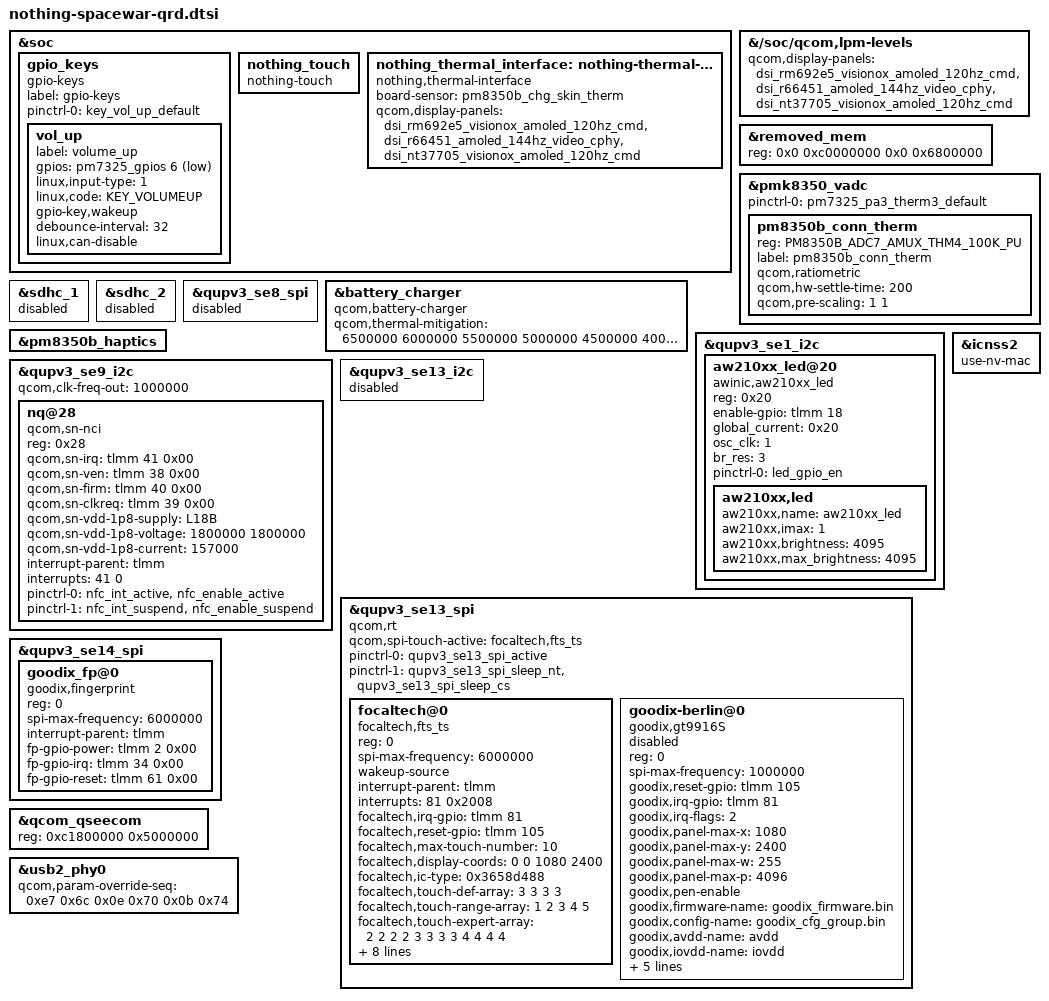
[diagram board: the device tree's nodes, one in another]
// This file is for attribution of nothing spacewar platform only

#include <dt-bindings/gpio/gpio.h>
#include <dt-bindings/input/input.h>
#include "display/nothing-spacewar-sde-display.dtsi"

&soc {
	gpio_keys {
		compatible = "gpio-keys";
		label = "gpio-keys";

		pinctrl-names = "default";
		pinctrl-0 = <&key_vol_up_default>;

		vol_up {
			label = "volume_up";
			gpios = <&pm7325_gpios 6 GPIO_ACTIVE_LOW>;
			linux,input-type = <1>;
			linux,code = <KEY_VOLUMEUP>;
			gpio-key,wakeup;
			debounce-interval = <32>;
			linux,can-disable;
		};
	};

	nothing_touch {
		compatible = "nothing-touch";
		status = "okay";

	};

	nothing_thermal_interface: nothing-thermal-interface {
		compatible = "nothing,thermal-interface";
		board-sensor = "pm8350b_chg_skin_therm";
		qcom,display-panels = <&dsi_rm692e5_visionox_amoled_120hz_cmd
				       &dsi_r66451_amoled_144hz_video_cphy
				       &dsi_nt37705_visionox_amoled_120hz_cmd>;
	};
};

&{/soc/qcom,lpm-levels} {
	qcom,display-panels = <&dsi_rm692e5_visionox_amoled_120hz_cmd
			       &dsi_r66451_amoled_144hz_video_cphy
			       &dsi_nt37705_visionox_amoled_120hz_cmd>;
};

&removed_mem {
	reg = <0x0 0xc0000000 0x0 0x6800000>;
};

/*
 * PMK8350 device specific diff for Nothing Spacewar platform
 */
&pmk8350_vadc {
	pinctrl-names = "default";
	pinctrl-0 = <&pm7325_pa3_therm3_default>;

	pm8350b_conn_therm {
		reg = <PM8350B_ADC7_AMUX_THM4_100K_PU>;
		label = "pm8350b_conn_therm";
		qcom,ratiometric;
		qcom,hw-settle-time = <200>;
		qcom,pre-scaling = <1 1>;
	};
};

&sdhc_1 {
	status = "disabled";
};

&sdhc_2 {
	status = "disabled";
};

&qupv3_se8_spi {
	status = "disabled";
};

&battery_charger {
	compatible = "qcom,battery-charger";
	qcom,thermal-mitigation = <6500000 6000000 5500000 5000000 4500000 4000000
				3500000 3000000 2650000 2200000 1800000 1400000
				1000000 600000 300000 0>;
	#cooling-cells = <2>;
};

&pm8350b_haptics {
	status = "okay";
};

&qupv3_se1_i2c {
	status = "okay";

	aw210xx_led@20 {
		compatible = "awinic,aw210xx_led";
		reg = <0x20>;
		enable-gpio = <&tlmm 18 0x00>;
		global_current = <0x20>;
		osc_clk = <1>;
		br_res = <3>;
		pinctrl-names = "default";
		pinctrl-0 = <&led_gpio_en>;
		status = "okay";
		aw210xx,led {
			aw210xx,name = "aw210xx_led";
			aw210xx,imax = <1>;
			aw210xx,brightness = <4095>;
			aw210xx,max_brightness = <4095>;
		};
	};
};

&qupv3_se9_i2c {
	status = "okay";
	qcom,clk-freq-out = <1000000>;
	#address-cells = <1>;
	#size-cells = <0>;

	nq@28 {
		compatible = "qcom,sn-nci";
		reg = <0x28>;
		qcom,sn-irq = <&tlmm 41 0x00>;
		qcom,sn-ven = <&tlmm 38 0x00>;
		qcom,sn-firm = <&tlmm 40 0x00>;
		qcom,sn-clkreq = <&tlmm 39 0x00>;
		qcom,sn-vdd-1p8-supply = <&L18B>;
		qcom,sn-vdd-1p8-voltage = <1800000 1800000>;
		qcom,sn-vdd-1p8-current = <157000>;
		interrupt-parent = <&tlmm>;
		interrupts = <41 0>;
		interrupt-names = "nfc_irq";
		pinctrl-names = "nfc_active", "nfc_suspend";
		pinctrl-0 = <&nfc_int_active &nfc_enable_active>;
		pinctrl-1 = <&nfc_int_suspend &nfc_enable_suspend>;
		status = "okay";
	};
};

&qupv3_se13_i2c {
	status = "disabled";
};

&qupv3_se13_spi {
	status = "okay";
	qcom,rt;
	qcom,spi-touch-active = "focaltech,fts_ts";
	pinctrl-names = "default", "sleep";
	pinctrl-0 = <&qupv3_se13_spi_active>;
	pinctrl-1 = <&qupv3_se13_spi_sleep_nt &qupv3_se13_spi_sleep_cs>;
	#address-cells = <1>;
	#size-cells = <0>;

	/* FocalTech FT5662 */
	focaltech@0 {
		status = "okay";
		compatible = "focaltech,fts_ts";
		reg = <0>;
		spi-max-frequency = <6000000>;
		wakeup-source;

		interrupt-parent = <&tlmm>;
		interrupts = <81 0x2008>;

		focaltech,irq-gpio = <&tlmm 81 0x2008>;
		focaltech,reset-gpio = <&tlmm 105 0x00>;
		focaltech,max-touch-number = <10>;
		focaltech,display-coords = <0 0 1080 2400>;
		focaltech,ic-type = <0x3658d488>;

		/* Nothing touch-feature tuning */
		focaltech,touch-def-array = <3 3 3 3>;
		focaltech,touch-range-array = <1 2 3 4 5>;
		focaltech,touch-expert-array = <2 2 2 2
						3 3 3 3
						4 4 4 4>;

		vdd-supply   = <&L3C>;
		avdd-supply  = <&L3C>;
		iovdd-supply = <&L8C>;

		panel = <&dsi_rm692e5_visionox_amoled_120hz_cmd
			 &dsi_r66451_amoled_144hz_video_cphy>;

		pinctrl-names = "pmx_ts_active", "pmx_ts_suspend", "pmx_ts_release";
		pinctrl-0 = <&ts_active>;
		pinctrl-1 = <&ts_int_suspend &ts_reset_suspend>;
		pinctrl-2 = <&ts_release>;
	};

	/* Goodix GT9916S (Berlin-D) */
	goodix-berlin@0 {
		status = "disabled";
		compatible = "goodix,gt9916S", "goodix,brl-d";
		reg = <0>;
		spi-max-frequency = <1000000>;

		goodix,reset-gpio = <&tlmm 105 0x00>;
		goodix,irq-gpio   = <&tlmm 81 0x2800>;
		goodix,irq-flags  = <2>;
		goodix,panel-max-x = <1080>;
		goodix,panel-max-y = <2400>;
		goodix,panel-max-w = <255>;
		goodix,panel-max-p = <4096>;
		goodix,pen-enable;
		goodix,firmware-name = "goodix_firmware.bin";
		goodix,config-name   = "goodix_cfg_group.bin";
		goodix,avdd-name  = "avdd";
		goodix,iovdd-name = "iovdd";
 
		qcom,display-panels = <&dsi_rm692e5_visionox_amoled_120hz_cmd
				       &dsi_r66451_amoled_144hz_video_cphy>;

 		avdd-supply  = <&L3C>;
		iovdd-supply = <&L8C>;
	};
};

&qupv3_se14_spi {
	status = "okay";

	goodix_fp@0 {
		compatible = "goodix,fingerprint";
		reg = <0>;
		spi-max-frequency = <6000000>;
		interrupt-parent = <&tlmm>;
		fp-gpio-power = <&tlmm 2 0x00>;
		fp-gpio-irq = <&tlmm 34 0x00>;
		fp-gpio-reset = <&tlmm 61 0x00>;
		status = "okay";
	};
};

&qcom_qseecom {
	reg = <0xc1800000 0x5000000>;
	reg-names = "secapp-region";
};

&sdhc_2 {
	status = "disabled";
};

&qupv3_se8_spi {
	status = "disabled";
};

&usb2_phy0 {
	qcom,param-override-seq =
		<0xe7 0x6c	/* override_x0 */
		 0x0e 0x70	/* override_x1 */
		 0x0b 0x74>;	/* override_x2 */
};

&icnss2 {
	use-nv-mac;
};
